# EQEP0 register map
Vendor: Texas Instruments
Peripheral module from a debugger description file (folder J7ES).
Registers are 32-bit, read-write, reset 0x0 unless marked. A register's access mark holds for its fields unless they carry their own. Offsets are as the file gives them; lines under a group give offsets from that group; [hi:lo] are bit positions; {n}, {i} and the like mark numbered series; 'fields as' and 'values as' point back to an identical list; <NAME> marks a mode.

## EQEP0
0x00 EQEP_QPOSCNT — QEP Position Counter.
  [31:0] POSCNT — This 32-bit position counter register counts up/down on every QEP pulse based on direction input.
0x04 EQEP_QPOSINIT — Position Counter Initialization Register.
  [31:0] INITPOS — This register contains the position value to be used to initialize the position counter based on external strobe or Index event.
0x08 EQEP_QPOSMAX — Maximum Position Count Register.
  [31:0] MAXPOS — This register contains the maximum Position counter value for error checking in index reset mode or to reset the Position counter based on the maximum count value.
0x0C EQEP_QPOSCMP — Position Compare Register.
  [31:0] POSCMP — Position compare value in this register is compared with the position counter (
0x10 EQEP_QPOSILAT ro — Index Position Latch Register.
  [31:0] IPOSLAT — Position counter value can be latched into this register on index event as defined by the
0x14 EQEP_QPOSSLAT ro — Strobe Position Latch Register
  [31:0] SPOSLAT — Position counter value can be latched into this register on strobe event as defined by the
0x18 EQEP_QPOSLAT ro — QEP Position Counter Latch.
  [31:0] POSLAT — Position counter value can be latched into this register on unit time out event.
0x1C EQEP_QUTMR — QEP Unit Timer.
  [31:0] UNITTMR — This register acts as time base for unit time event generation.
0x20 EQEP_QUPRD — QEP Unit Period Register.
  [31:0] UNITPRD — This register contains the period count for unit timer to generate periodic unit time events to latch the EQEP position information at periodic interval and optionally to generate interrupt.
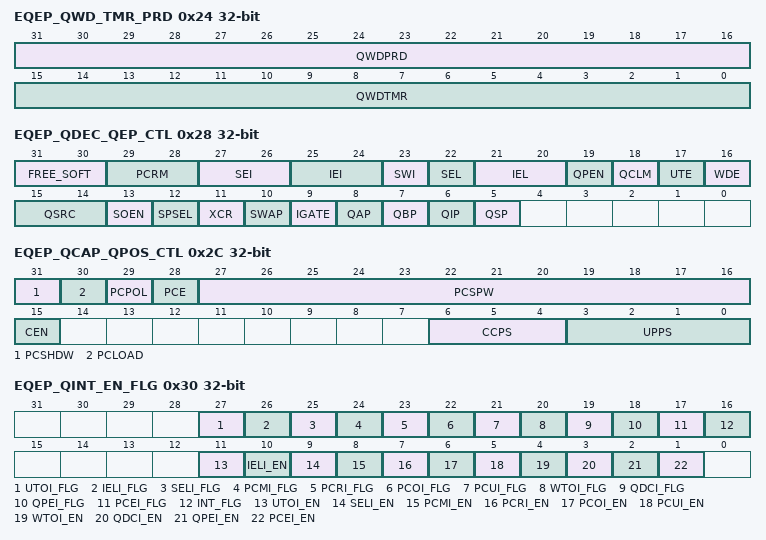
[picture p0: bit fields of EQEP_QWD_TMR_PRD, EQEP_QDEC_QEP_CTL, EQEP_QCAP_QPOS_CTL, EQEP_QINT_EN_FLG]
0x24 EQEP_QWD_TMR_PRD — QEP Watchdog Timer and Period Register.
  [31:16] QWDPRD — This field contains the time-out count for the QEP peripheral watch dog timer.
  [15:0] QWDTMR — This field acts as time base for watch dog to detect stalls.
0x28 EQEP_QDEC_QEP_CTL — Quadrature Decoder and QEP Control Register.
  [31:30] FREE_SOFT — POSCNT Behavior:
  [29:28] PCRM — Position Counter Reset mode:
  [27:26] SEI — Strobe Event Initialization of Position Counter:
  [25:24] IEI — Index Event Initialization of Position Counter:
  [23] SWI — Software Initialization of Position Counter:
  [22] SEL — Strobe Event Latch of Position Counter:
  [21:20] IEL — Index Event Latch of Position Counter (Software Index Marker):
  [19] QPEN — Quadrature Position counter Enable/Software Reset:
  [18] QCLM — EQEP Capture Latch mode:
  [17] UTE — QEP Unit Timer Enable:
  [16] WDE — QEP Watchdog Enable:
  [15:14] QSRC — Position Counter Source selection:
  [13] SOEN — Enable Position Compare Sync Output:
  [12] SPSEL — Sync output pin selection:
  [11] XCR — External Clock Rate:
  [10] SWAP — CLK/DIR signal source for Position Counter: 0 Quadrature clock inputs are not swapped 1 Quadrature clock inputs are swapped
  [9] IGATE — Index Pulse Gating Option:
  [8] QAP — QEPA input polarity:
  [7] QBP — QEPB input polarity:
  [6] QIP — QEPI input polarity:
  [5] QSP — QEPS input polarity:
0x2C EQEP_QCAP_QPOS_CTL — QEP Capture and Position Compare Control Register.
  [31] PCSHDW — Position-compare shadow enable:
  [30] PCLOAD — Position Compare Shadow Load Mode:
  [29] PCPOL — Polarity of sync output:
  [28] PCE — Position compare enable/disable:
  [27:16] PCSPW — Select pulse width period in EQEP_FICLK cycles:
  [15] CEN — Enable EQEP Capture:
  [6:4] CCPS — EQEP Capture timer clock prescalar:
  [3:0] UPPS — Unit Position Event prescalar:
0x30 EQEP_QINT_EN_FLG access per field — QEP Interrupt Control and Flag Register.
  [27] UTOI_FLG ro — Unit Time Out Interrupt Flag:
  [26] IELI_FLG ro — Index Event Latch Interrupt Flag:
  [25] SELI_FLG ro — Strobe Event Latch Interrupt Flag:
  [24] PCMI_FLG ro — EQEP Compare Match Event Interrupt Flag:
  [23] PCRI_FLG ro — Position Compare Ready Interrupt Flag:
  [22] PCOI_FLG ro — Position Counter Overflow Interrupt Flag:
  [21] PCUI_FLG ro — Position Counter Underflow Interrupt Flag:
  [20] WTOI_FLG ro — Watchdog Timeout Interrupt Flag:
  [19] QDCI_FLG ro — Quadrature Direction Change Interrupt Flag:
  [18] QPEI_FLG ro — Quadrature Phase Error Interrupt Flag:
  [17] PCEI_FLG ro — Position Counter Error Interrupt Flag:
  [16] INT_FLG ro — Global Interrupt Status Flag:
  [11] UTOI_EN rw — Unit Time Out Interrupt Enable:
  [10] IELI_EN rw — Index Event Latch Interrupt Enable:
  [9] SELI_EN rw — Strobe Event Latch Interrupt Enable:
  [8] PCMI_EN rw — Position Compare Match Interrupt Enable:
  [7] PCRI_EN rw — Position Compare Ready Interrupt Enable:
  [6] PCOI_EN rw — Position Counter Overflow Interrupt Enable:
  [5] PCUI_EN rw — Position Counter Underflow Interrupt Enable:
  [4] WTOI_EN rw — Watchdog Time Out Interrupt Enable:
  [3] QDCI_EN rw — Quadrature Direction Change Interrupt Enable:
  [2] QPEI_EN rw — Quadrature Phase Error Interrupt Enable:
  [1] PCEI_EN rw — Position Counter Error Interrupt Enable:
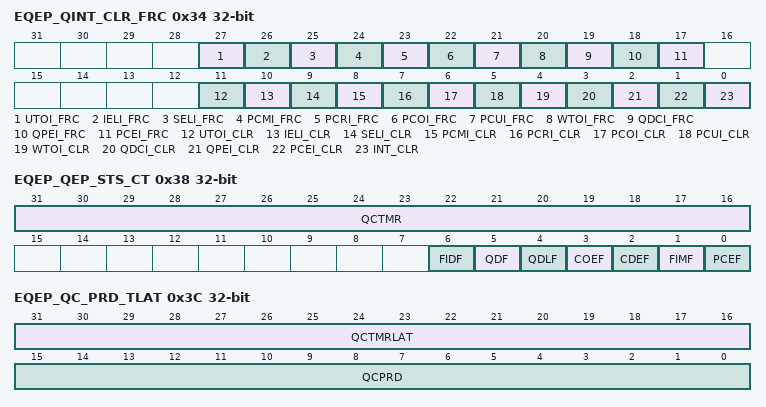
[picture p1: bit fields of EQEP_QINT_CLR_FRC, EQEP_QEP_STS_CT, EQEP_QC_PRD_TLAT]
0x34 EQEP_QINT_CLR_FRC access not given — QEP Interrupt Clear and Forcing Register.
  [27] UTOI_FRC — Unit Time Out Interrupt Force: (access W1S)
  [26] IELI_FRC — Index Event Latch Interrupt Force: (access W1S)
  [25] SELI_FRC — Strobe Event Latch Interrupt Force: (access W1S)
  [24] PCMI_FRC — Position Compare Match Interrupt Force: (access W1S)
  [23] PCRI_FRC — Position Compare Ready Interrupt Force: (access W1S)
  [22] PCOI_FRC — Position Counter Overflow Interrupt Force: (access W1S)
  [21] PCUI_FRC — Position Counter Underflow Interrupt Force: (access W1S)
  [20] WTOI_FRC — Watchdog Time Out Interrupt Force: (access W1S)
  [19] QDCI_FRC — Quadrature Direction Change Interrupt Force: (access W1S)
  [18] QPEI_FRC — Quadrature Phase Error Interrupt Force: (access W1S)
  [17] PCEI_FRC — Position Counter Error Interrupt Force: (access W1S)
  [11] UTOI_CLR — Clear Unit Time Out Interrupt Flag: (access W1C)
  [10] IELI_CLR — Clear Index Event Latch Interrupt Flag: (access W1C)
  [9] SELI_CLR — Clear Strobe Event Latch Interrupt Flag: (access W1C)
  [8] PCMI_CLR — Clear QEP Compare Match Event Interrupt Flag: (access W1C)
  [7] PCRI_CLR — Clear Position Compare Ready Interrupt Flag: (access W1C)
  [6] PCOI_CLR — Clear Position Counter Overflow Interrupt Flag: (access W1C)
  [5] PCUI_CLR — Clear Position Counter Underflow Interrupt Flag: (access W1C)
  [4] WTOI_CLR — Clear Watchdog Timeout Interrupt Flag: (access W1C)
  [3] QDCI_CLR — Clear Quadrature Direction Change Interrupt Flag: (access W1C)
  [2] QPEI_CLR — Clear Quadrature Phase Error Interrupt Flag: (access W1C)
  [1] PCEI_CLR — Clear Position Counter Error Interrupt Flag: (access W1C)
  [0] INT_CLR — Global Interrupt Clear Flag: (access W1C)
0x38 EQEP_QEP_STS_CT access not given — QEP Status and Capture Timer Register.
  [31:16] QCTMR rw — This field provides time base for edge capture unit.
  [6] FIDF ro — Direction on First Index Marker. Status of the direction is latched on first index event marker.
  [5] QDF ro — Quadrature Direction flag:
  [4] QDLF ro — EQEP Direction Latch Flag. Status of Direction is latched on every index event marker.
  [3] COEF — Capture Overflow Error Flag: (access RW1C)
  [2] CDEF — Capture Direction Error Flag:1h = Direction change occurred between the capture position event (access RW1C)
  [1] FIMF — First Index Marker Flag: 0h = Sticky bit, cleared by writing 1h (access RW1C)
  [0] PCEF ro — Position Counter Error Flag. This bit is not sticky bit and it is updated for every index event.
0x3C EQEP_QC_PRD_TLAT access per field — QEP Capture Period and Timer Latch Register.
  [31:16] QCTMRLAT ro — QEP Capture timer value can be latched into this register on two events:
  [15:0] QCPRD rw — This field holds the period count value between the last successive EQEP position events.
0x40 EQEP_QCPRDLAT ro — QEP Capture Period Latch.
  [15:0] QCPRDLAT — EQEP capture period value can be latched into this register on two events:
0x5C EQEP_PID ro reset 0x44D31903 — Peripheral ID Register.
  [31:0] REVISION — TI internal data. Identifies revision of peripheral.
